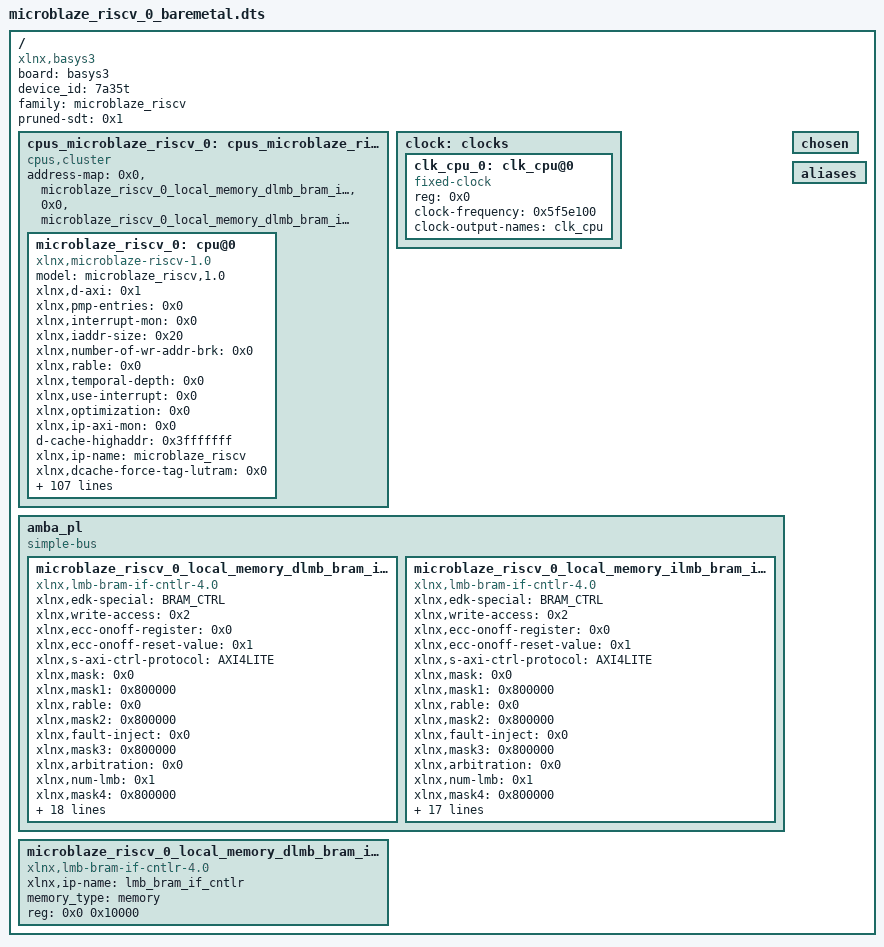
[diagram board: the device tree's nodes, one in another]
/dts-v1/;

/ {
        board = "basys3";
        compatible = "xlnx,basys3";
        device_id = "7a35t";
        #address-cells = <0x1>;
        #size-cells = <0x1>;
        family = "microblaze_riscv";
        pruned-sdt = <0x1>;

        cpus_microblaze_riscv_0: cpus_microblaze_riscv@0 {
                #cpu-mask-cells = <0x1>;
                compatible = "cpus,cluster";
                #address-cells = <0x1>;
                #size-cells = <0x0>;
                address-map = <0x0 &microblaze_riscv_0_local_memory_dlmb_bram_if_cntlr_memory 0x0 0x10000>,
                 <0x0 &microblaze_riscv_0_local_memory_dlmb_bram_if_cntlr 0x0 0x10000>;
                #ranges-address-cells = <0x1>;
                #ranges-size-cells = <0x1>;
                phandle = <0x4>;

                microblaze_riscv_0: cpu@0 {
                        model = "microblaze_riscv,1.0";
                        xlnx,d-axi = <0x1>;
                        xlnx,pmp-entries = <0x0>;
                        xlnx,interrupt-mon = <0x0>;
                        xlnx,iaddr-size = <0x20>;
                        xlnx,number-of-wr-addr-brk = <0x0>;
                        xlnx,rable = <0x0>;
                        xlnx,temporal-depth = <0x0>;
                        xlnx,use-interrupt = <0x0>;
                        xlnx,optimization = <0x0>;
                        xlnx,ip-axi-mon = <0x0>;
                        d-cache-highaddr = <0x3fffffff>;
                        xlnx,ip-name = "microblaze_riscv";
                        xlnx,dcache-force-tag-lutram = <0x0>;
                        xlnx,pc-width = <0x10>;
                        xlnx,interrupt-is-edge = <0x0>;
                        reg = <0x0>;
                        xlnx,async-interrupt = <0x1>;
                        xlnx,use-mmu = <0x0>;
                        xlnx,icache-victims = <0x0>;
                        xlnx,use-bitman-a = <0x0>;
                        xlnx,d-lmb-mon = <0x0>;
                        xlnx,d-lmb-protocol = <0x0>;
                        xlnx,use-bitman-b = <0x0>;
                        xlnx,use-bitman-c = <0x0>;
                        xlnx,dc-axi-mon = <0x0>;
                        xlnx,debug-trace-async-reset = <0x0>;
                        xlnx,trace = <0x0>;
                        xlnx,part = "xc7a35tcpg236-1";
                        xlnx,use-config-reset = <0x0>;
                        xlnx,i-lmb-mon = <0x0>;
                        xlnx,dcache-byte-size = <0x2000>;
                        xlnx,ill-instr-exception = <0x1>;
                        compatible = "xlnx,microblaze-riscv-1.0", "xlnx,microblaze_riscv";
                        xlnx,data-size = <0x20>;
                        xlnx,fault-tolerant = <0x0>;
                        xlnx,use-sleep = <0x0>;
                        xlnx,debug-trace-size = <0x0>;
                        xlnx,pmp-granularity = <0x2>;
                        xlnx,mmu-privileged-instr = <0x0>;
                        d-cache-line-size = <0x10>;
                        xlnx,d-lmb = <0x1>;
                        xlnx,enable-discrete-ports = <0x0>;
                        clock-frequency = <0x5f5e100>;
                        xlnx,debug-interface = <0x0>;
                        xlnx,use-ext-brk = <0x0>;
                        xlnx,daddr-size = <0x20>;
                        xlnx,debug-enabled = <0x1>;
                        xlnx,num-sync-ff-dbg-trace-clk = <0x2>;
                        xlnx,i-lmb-protocol = <0x0>;
                        xlnx,fsl-exception = <0x0>;
                        xlnx,use-extended-fsl-instr = <0x0>;
                        xlnx,dp-axi-mon = <0x0>;
                        xlnx,impid = <0x1>;
                        device_type = "cpu";
                        xlnx,branch-target-cache-size = <0x0>;
                        xlnx,dcache-use-writeback = <0x0>;
                        xlnx,use-bitman-s = <0x0>;
                        bus-handle = <0x3>;
                        xlnx,icache-line-len = <0x4>;
                        xlnx,base-vectors = <0x0>;
                        xlnx,ecc-use-ce-exception = <0x0>;
                        xlnx,edk-special = "microblaze_riscv";
                        xlnx,use-dcache = <0x0>;
                        xlnx,use-barrel = <0x1>;
                        xlnx,use-muldiv = <0x2>;
                        xlnx,addr-size = <0x20>;
                        xlnx,debug-external-trace = <0x0>;
                        xlnx,piaddr-size = <0x20>;
                        xlnx,misaligned-exceptions = <0x1>;
                        xlnx,use-bitman = <0x0>;
                        xlnx,num-sync-ff-clk-debug = <0x2>;
                        xlnx,debug-event-counters = <0x0>;
                        xlnx,use-atomic = <0x1>;
                        xlnx,i-axi = <0x0>;
                        xlnx,g-template-list = <0x6>;
                        xlnx,icache-streams = <0x0>;
                        xlnx,dcache-line-len = <0x4>;
                        xlnx,num-sync-ff-clk = <0x2>;
                        xlnx,edk-iptype = "PROCESSOR";
                        xlnx,num-sync-ff-dbg-clk = <0x1>;
                        xlnx,interconnect = <0x2>;
                        xlnx,hartid = <0x0>;
                        xlnx,debug-latency-counters = <0x0>;
                        xlnx,use-fpu = <0x1>;
                        xlnx,icache-byte-size = <0x2000>;
                        xlnx,edge-is-positive = <0x1>;
                        xlnx,use-icache = <0x0>;
                        d-cache-size = <0x2000>;
                        xlnx,memory-ip-list = "microblaze_riscv_0_local_memory_dlmb_bram_if_cntlr_memory", "microblaze_riscv_0_local_memory_ilmb_bram_if_cntlr_memory";
                        xlnx,async-wakeup = <0x3>;
                        xlnx,use-non-secure = <0x0>;
                        xlnx,s-axi = <0x0>;
                        xlnx,number-of-rd-addr-brk = <0x0>;
                        d-cache-baseaddr = <0x0>;
                        xlnx,use-compression = <0x1>;
                        xlnx,avoid-primitives = <0x0>;
                        xlnx,use-counters = <0x1>;
                        xlnx,lockstep-slave = <0x0>;
                        xlnx,use-ext-nm-brk = <0x0>;
                        xlnx,pdaddr-size = <0x20>;
                        xlnx,instr-size = <0x20>;
                        xlnx,i-lmb = <0x1>;
                        xlnx,lockstep-select = <0x0>;
                        xlnx,lmb-data-size = <0x20>;
                        xlnx,ic-axi-mon = <0x0>;
                        xlnx,num-sync-ff-clk-irq = <0x1>;
                        xlnx,fsl-links = <0x0>;
                        timebase-frequency = <0x5f5e100>;
                        xlnx,archid = <0x1>;
                        xlnx,icache-force-tag-lutram = <0x0>;
                        xlnx,dcache-data-width = <0x0>;
                        xlnx,dcache-victims = <0x0>;
                        xlnx,use-branch-target-cache = <0x0>;
                        xlnx,debug-profile-size = <0x0>;
                        xlnx,lockstep-master = <0x0>;
                        xlnx,freq = <0x5f5e100>;
                        xlnx,number-of-pc-brk = <0x1>;
                        xlnx,imprecise-exceptions = <0x0>;
                        xlnx,icache-data-width = <0x0>;
                        xlnx,debug-counter-width = <0x40>;
                        phandle = <0x5>;
                };
        };

        clock: clocks {
                #address-cells = <0x1>;
                #size-cells = <0x0>;
                phandle = <0x6>;

                clk_cpu_0: clk_cpu@0 {
                        compatible = "fixed-clock";
                        reg = <0x0>;
                        clock-frequency = <0x5f5e100>;
                        clock-output-names = "clk_cpu";
                        #clock-cells = <0x0>;
                        phandle = <0x7>;
                };
        };

        amba_pl: amba_pl {
                ranges;
                compatible = "simple-bus";
                #address-cells = <0x1>;
                #size-cells = <0x1>;
                phandle = <0x3>;

                microblaze_riscv_0_local_memory_dlmb_bram_if_cntlr: lmb_bram_if_cntlr@0 {
                        xlnx,edk-special = "BRAM_CTRL";
                        xlnx,write-access = <0x2>;
                        compatible = "xlnx,lmb-bram-if-cntlr-4.0";
                        xlnx,ecc-onoff-register = <0x0>;
                        xlnx,ecc-onoff-reset-value = <0x1>;
                        xlnx,s-axi-ctrl-protocol = "AXI4LITE";
                        xlnx,mask = <0x0>;
                        xlnx,mask1 = <0x800000>;
                        xlnx,rable = <0x0>;
                        xlnx,mask2 = <0x800000>;
                        xlnx,fault-inject = <0x0>;
                        xlnx,mask3 = <0x800000>;
                        xlnx,arbitration = <0x0>;
                        xlnx,num-lmb = <0x1>;
                        xlnx,mask4 = <0x800000>;
                        reg = <0x0 0x10000>;
                        xlnx,s-axi-ctrl-addr-width = <0x20>;
                        xlnx,mask5 = <0x800000>;
                        xlnx,ecc-status-registers = <0x0>;
                        xlnx,mask6 = <0x800000>;
                        xlnx,lmb-protocol = <0x0>;
                        xlnx,ce-counter-width = <0x0>;
                        xlnx,mask7 = <0x800000>;
                        xlnx,ecc = <0x0>;
                        xlnx,edk-iptype = "PERIPHERAL";
                        xlnx,lmb-dwidth = <0x20>;
                        xlnx,ce-failing-registers = <0x0>;
                        xlnx,interconnect = <0x0>;
                        xlnx,ue-failing-registers = <0x0>;
                        xlnx,data-width = <0x20>;
                        xlnx,s-axi-ctrl-data-width = <0x20>;
                        xlnx,bram-awidth = <0x20>;
                        xlnx,lmb-awidth = <0x20>;
                        phandle = <0x2>;
                };

                microblaze_riscv_0_local_memory_ilmb_bram_if_cntlr: lmb_bram_if_cntlr@1 {
                        xlnx,edk-special = "BRAM_CTRL";
                        xlnx,write-access = <0x2>;
                        compatible = "xlnx,lmb-bram-if-cntlr-4.0";
                        xlnx,ecc-onoff-register = <0x0>;
                        xlnx,ecc-onoff-reset-value = <0x1>;
                        xlnx,s-axi-ctrl-protocol = "AXI4LITE";
                        xlnx,mask = <0x0>;
                        xlnx,mask1 = <0x800000>;
                        xlnx,rable = <0x0>;
                        xlnx,mask2 = <0x800000>;
                        xlnx,fault-inject = <0x0>;
                        xlnx,mask3 = <0x800000>;
                        xlnx,arbitration = <0x0>;
                        xlnx,num-lmb = <0x1>;
                        xlnx,mask4 = <0x800000>;
                        reg = <0x0 0x10000>;
                        xlnx,s-axi-ctrl-addr-width = <0x20>;
                        xlnx,mask5 = <0x800000>;
                        xlnx,ecc-status-registers = <0x0>;
                        xlnx,mask6 = <0x800000>;
                        xlnx,lmb-protocol = <0x0>;
                        xlnx,ce-counter-width = <0x0>;
                        xlnx,mask7 = <0x800000>;
                        xlnx,ecc = <0x0>;
                        xlnx,edk-iptype = "PERIPHERAL";
                        xlnx,lmb-dwidth = <0x20>;
                        xlnx,ce-failing-registers = <0x0>;
                        xlnx,interconnect = <0x0>;
                        xlnx,ue-failing-registers = <0x0>;
                        xlnx,s-axi-ctrl-data-width = <0x20>;
                        xlnx,bram-awidth = <0x20>;
                        xlnx,lmb-awidth = <0x20>;
                        phandle = <0x8>;
                };
        };

        microblaze_riscv_0_local_memory_dlmb_bram_if_cntlr_memory: memory@0 {
                compatible = "xlnx,lmb-bram-if-cntlr-4.0";
                xlnx,ip-name = "lmb_bram_if_cntlr";
                device_type = "memory";
                memory_type = "memory";
                reg = <0x0 0x10000>;
                phandle = <0x1>;
        };

        chosen {
        };

        aliases {
        };

        __symbols__ {
                cpus_microblaze_riscv_0 = "/cpus_microblaze_riscv@0";
                microblaze_riscv_0 = "/cpus_microblaze_riscv@0/cpu@0";
                clock = "/clocks";
                clk_cpu_0 = "/clocks/clk_cpu@0";
                amba_pl = "/amba_pl";
                microblaze_riscv_0_local_memory_dlmb_bram_if_cntlr = "/amba_pl/lmb_bram_if_cntlr@0";
                microblaze_riscv_0_local_memory_ilmb_bram_if_cntlr = "/amba_pl/lmb_bram_if_cntlr@1";
                microblaze_riscv_0_local_memory_dlmb_bram_if_cntlr_memory = "/memory@0";
        };
};
